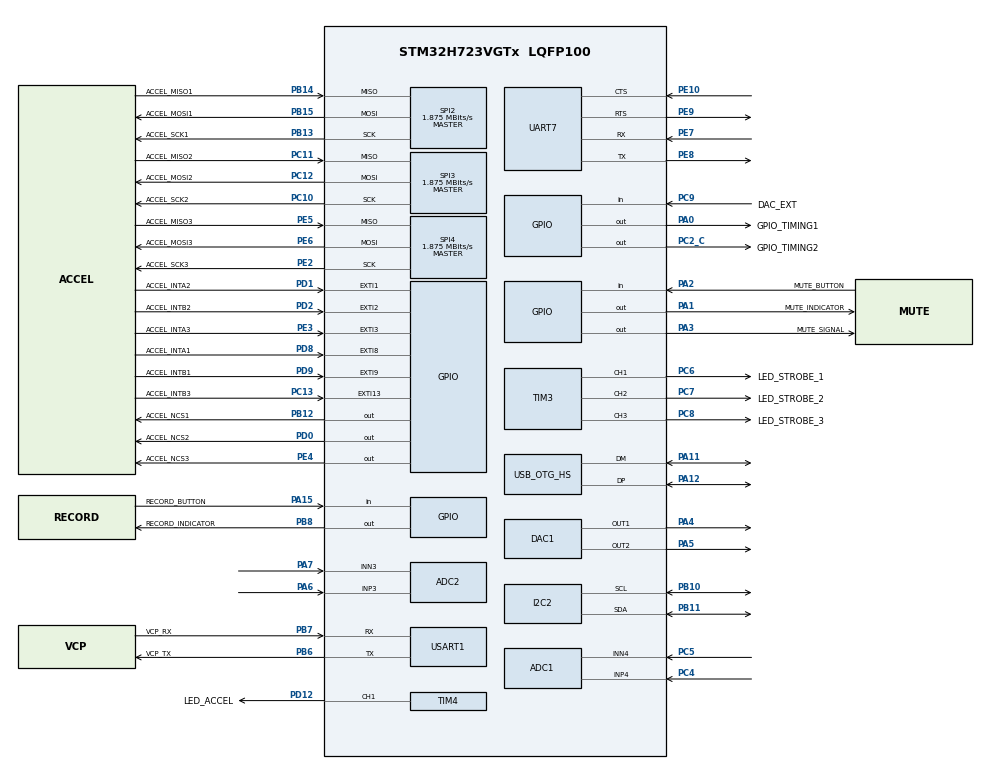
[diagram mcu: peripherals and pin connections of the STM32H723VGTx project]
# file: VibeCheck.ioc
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ADC1.Channel-0\#ChannelRegularConversion=ADC_CHANNEL_4
ADC1.ClockPrescaler=ADC_CLOCK_ASYNC_DIV2
ADC1.NbrOfConversionFlag=1
ADC1.OffsetNumber-0\#ChannelRegularConversion=ADC_OFFSET_NONE
ADC1.OffsetSignedSaturation-0\#ChannelRegularConversion=DISABLE
ADC1.Rank-0\#ChannelRegularConversion=1
ADC1.SamplingTime-0\#ChannelRegularConversion=ADC_SAMPLETIME_1CYCLE_5
ADC1.SingleDiff-0\#ChannelRegularConversion=ADC_DIFFERENTIAL_ENDED
ADC1.master=1
ADC2.Channel-1\#ChannelRegularConversion=ADC_CHANNEL_3
ADC2.ClockPrescaler=ADC_CLOCK_ASYNC_DIV2
ADC2.NbrOfConversionFlag=1
ADC2.OffsetNumber-1\#ChannelRegularConversion=ADC_OFFSET_NONE
ADC2.OffsetSignedSaturation-1\#ChannelRegularConversion=DISABLE
ADC2.Rank-1\#ChannelRegularConversion=1
ADC2.SamplingTime-1\#ChannelRegularConversion=ADC_SAMPLETIME_1CYCLE_5
ADC2.SingleDiff-1\#ChannelRegularConversion=ADC_DIFFERENTIAL_ENDED
CORTEX_M7.default_mode_Activation=1
DAC1.DAC1_OutputBuffer-DAC_OUT1=DAC_OUTPUTBUFFER_DISABLE
DAC1.DAC2_OutputBuffer-DAC_OUT2=DAC_OUTPUTBUFFER_DISABLE
DAC1.DAC_Channel-DAC_OUT1=DAC_CHANNEL_1
DAC1.DAC_Channel-DAC_OUT2=DAC_CHANNEL_2
DAC1.DAC_Trigger-DAC_OUT1=DAC_TRIGGER_T1_TRGO
DAC1.DAC_Trigger-DAC_OUT2=DAC_TRIGGER_T1_TRGO
Dma.DAC1_CH1.0.Direction=DMA_MEMORY_TO_PERIPH
Dma.DAC1_CH1.0.EventEnable=DISABLE
Dma.DAC1_CH1.0.FIFOMode=DMA_FIFOMODE_DISABLE
Dma.DAC1_CH1.0.Instance=DMA1_Stream0
Dma.DAC1_CH1.0.MemDataAlignment=DMA_MDATAALIGN_WORD
Dma.DAC1_CH1.0.MemInc=DMA_MINC_ENABLE
Dma.DAC1_CH1.0.Mode=DMA_CIRCULAR
Dma.DAC1_CH1.0.PeriphDataAlignment=DMA_PDATAALIGN_WORD
Dma.DAC1_CH1.0.PeriphInc=DMA_PINC_DISABLE
Dma.DAC1_CH1.0.Polarity=HAL_DMAMUX_REQ_GEN_RISING
Dma.DAC1_CH1.0.Priority=DMA_PRIORITY_LOW
Dma.DAC1_CH1.0.RequestNumber=1
Dma.DAC1_CH1.0.SignalID=NONE
Dma.DAC1_CH1.0.SyncEnable=DISABLE
Dma.DAC1_CH1.0.SyncPolarity=HAL_DMAMUX_SYNC_NO_EVENT
Dma.DAC1_CH1.0.SyncRequestNumber=1
Dma.DAC1_CH1.0.SyncSignalID=NONE
Dma.DAC1_CH2.1.Direction=DMA_MEMORY_TO_PERIPH
Dma.DAC1_CH2.1.EventEnable=DISABLE
Dma.DAC1_CH2.1.FIFOMode=DMA_FIFOMODE_DISABLE
Dma.DAC1_CH2.1.Instance=DMA1_Stream1
Dma.DAC1_CH2.1.MemDataAlignment=DMA_MDATAALIGN_WORD
Dma.DAC1_CH2.1.MemInc=DMA_MINC_ENABLE
Dma.DAC1_CH2.1.Mode=DMA_CIRCULAR
Dma.DAC1_CH2.1.PeriphDataAlignment=DMA_PDATAALIGN_WORD
Dma.DAC1_CH2.1.PeriphInc=DMA_PINC_DISABLE
Dma.DAC1_CH2.1.Polarity=HAL_DMAMUX_REQ_GEN_RISING
Dma.DAC1_CH2.1.Priority=DMA_PRIORITY_LOW
Dma.DAC1_CH2.1.RequestNumber=1
Dma.DAC1_CH2.1.SignalID=NONE
Dma.DAC1_CH2.1.SyncEnable=DISABLE
Dma.DAC1_CH2.1.SyncPolarity=HAL_DMAMUX_SYNC_NO_EVENT
Dma.DAC1_CH2.1.SyncRequestNumber=1
Dma.DAC1_CH2.1.SyncSignalID=NONE
Dma.Request0=DAC1_CH1
Dma.Request1=DAC1_CH2
Dma.Request2=TIM4_CH1
Dma.TIM4_CH1.2.Direction=DMA_MEMORY_TO_PERIPH
Dma.TIM4_CH1.2.EventEnable=DISABLE
Dma.TIM4_CH1.2.FIFOMode=DMA_FIFOMODE_DISABLE
Dma.TIM4_CH1.2.Instance=DMA1_Stream2
Dma.TIM4_CH1.2.MemDataAlignment=DMA_MDATAALIGN_HALFWORD
Dma.TIM4_CH1.2.MemInc=DMA_MINC_ENABLE
Dma.TIM4_CH1.2.Mode=DMA_NORMAL
Dma.TIM4_CH1.2.PeriphDataAlignment=DMA_PDATAALIGN_HALFWORD
Dma.TIM4_CH1.2.PeriphInc=DMA_PINC_DISABLE
Dma.TIM4_CH1.2.Polarity=HAL_DMAMUX_REQ_GEN_RISING
Dma.TIM4_CH1.2.Priority=DMA_PRIORITY_LOW
Dma.TIM4_CH1.2.RequestNumber=1
Dma.TIM4_CH1.2.SignalID=NONE
Dma.TIM4_CH1.2.SyncEnable=DISABLE
Dma.TIM4_CH1.2.SyncPolarity=HAL_DMAMUX_SYNC_NO_EVENT
Dma.TIM4_CH1.2.SyncRequestNumber=1
Dma.TIM4_CH1.2.SyncSignalID=NONE
I2C2.Timing=0x307075B1
Mcu.Family=STM32H7
Mcu.Name=STM32H723VGTx
Mcu.Package=LQFP100
NVIC.DMA1_Stream0_IRQn=true\:1\:1\:true\:false\:true\:false\:true\:true
NVIC.DMA1_Stream1_IRQn=true\:1\:1\:true\:false\:true\:false\:true\:true
NVIC.DMA1_Stream2_IRQn=true\:1\:1\:true\:false\:true\:false\:true\:true
NVIC.EXTI15_10_IRQn=true\:0\:0\:true\:false\:true\:true\:true\:true
NVIC.EXTI1_IRQn=true\:0\:0\:true\:false\:true\:true\:true\:true
NVIC.EXTI2_IRQn=true\:0\:0\:true\:false\:true\:true\:true\:true
NVIC.EXTI3_IRQn=true\:0\:0\:true\:false\:true\:true\:true\:true
NVIC.EXTI9_5_IRQn=true\:0\:0\:true\:false\:true\:true\:true\:true
NVIC.OTG_HS_IRQn=true\:1\:1\:true\:false\:true\:false\:true\:true
NVIC.PriorityGroup=NVIC_PRIORITYGROUP_2
NVIC.TIM3_IRQn=true\:1\:1\:true\:false\:true\:true\:true\:true
PA0.GPIO_Label=GPIO_TIMING1
PA0.Signal=GPIO_Output
PA1.GPIO_Label=MUTE_INDICATOR
PA1.PinState=GPIO_PIN_SET
PA1.Signal=GPIO_Output
PA11.Mode=Device_Only_FS
PA11.Signal=USB_OTG_HS_DM
PA12.Mode=Device_Only_FS
PA12.Signal=USB_OTG_HS_DP
PA13(JTMS/SWDIO).Mode=Trace_Asynchronous_SW
PA13(JTMS/SWDIO).Signal=DEBUG_JTMS-SWDIO
PA14(JTCK/SWCLK).Mode=Trace_Asynchronous_SW
PA14(JTCK/SWCLK).Signal=DEBUG_JTCK-SWCLK
PA15(JTDI).GPIO_Label=RECORD_BUTTON
PA15(JTDI).Signal=GPIO_Input
PA2.GPIO_Label=MUTE_BUTTON
PA2.Signal=GPIO_Input
PA3.GPIO_Label=MUTE_SIGNAL
PA3.PinState=GPIO_PIN_SET
PA3.Signal=GPIO_Output
PA4.Signal=COMP_DAC11_group
PA5.Signal=COMP_DAC12_group
PA6.Signal=ADCx_INP3
PA7.Signal=ADCx_INN3
PB10.Mode=I2C
PB10.Signal=I2C2_SCL
PB11.Mode=I2C
PB11.Signal=I2C2_SDA
PB12.GPIO_Label=ACCEL_NCS1
PB12.GPIO_Speed=GPIO_SPEED_FREQ_VERY_HIGH
PB12.PinState=GPIO_PIN_SET
PB12.Signal=GPIO_Output
PB13.GPIO_Label=ACCEL_SCK1
PB13.Mode=Full_Duplex_Master
PB13.Signal=SPI2_SCK
PB14.GPIO_Label=ACCEL_MISO1
PB14.Mode=Full_Duplex_Master
PB14.Signal=SPI2_MISO
PB15.GPIO_Label=ACCEL_MOSI1
PB15.Mode=Full_Duplex_Master
PB15.Signal=SPI2_MOSI
PB3(JTDO/TRACESWO).Mode=Trace_Asynchronous_SW
PB3(JTDO/TRACESWO).Signal=DEBUG_JTDO-SWO
PB6.GPIO_Label=VCP_TX
PB6.Mode=Asynchronous
PB6.Signal=USART1_TX
PB7.GPIO_Label=VCP_RX
PB7.Mode=Asynchronous
PB7.Signal=USART1_RX
PB8.GPIO_Label=RECORD_INDICATOR
PB8.Signal=GPIO_Output
PC10.GPIO_Label=ACCEL_SCK2
PC10.Mode=Full_Duplex_Master
PC10.Signal=SPI3_SCK
PC11.GPIO_Label=ACCEL_MISO2
PC11.Mode=Full_Duplex_Master
PC11.Signal=SPI3_MISO
PC12.GPIO_Label=ACCEL_MOSI2
PC12.Mode=Full_Duplex_Master
PC12.Signal=SPI3_MOSI
PC13.GPIO_Label=ACCEL_INTB3
PC13.Signal=GPXTI13
PC2_C.GPIO_Label=GPIO_TIMING2
PC2_C.Signal=GPIO_Output
PC4.Signal=ADCx_INP4
PC5.Signal=ADCx_INN4
PC6.GPIO_Label=LED_STROBE_1
PC6.Signal=S_TIM3_CH1
PC7.GPIO_Label=LED_STROBE_2
PC7.Signal=S_TIM3_CH2
PC8.GPIO_Label=LED_STROBE_3
PC8.Signal=S_TIM3_CH3
PC9.GPIO_Label=DAC_EXT
PC9.Signal=GPIO_Input
PD0.GPIO_Label=ACCEL_NCS2
PD0.GPIO_Speed=GPIO_SPEED_FREQ_VERY_HIGH
PD0.PinState=GPIO_PIN_SET
PD0.Signal=GPIO_Output
PD1.GPIO_Label=ACCEL_INTA2
PD1.Signal=GPXTI1
PD12.GPIO_Label=LED_ACCEL
PD12.Signal=S_TIM4_CH1
PD2.GPIO_Label=ACCEL_INTB2
PD2.Signal=GPXTI2
PD8.GPIO_Label=ACCEL_INTA1
PD8.Signal=GPXTI8
PD9.GPIO_Label=ACCEL_INTB1
PD9.Signal=GPXTI9
PE10.Mode=CTS_RTS
PE10.Signal=UART7_CTS
PE2.GPIO_Label=ACCEL_SCK3
PE2.Mode=Full_Duplex_Master
PE2.Signal=SPI4_SCK
PE3.GPIO_Label=ACCEL_INTA3
PE3.Signal=GPXTI3
PE4.GPIO_Label=ACCEL_NCS3
PE4.GPIO_Speed=GPIO_SPEED_FREQ_VERY_HIGH
PE4.PinState=GPIO_PIN_SET
PE4.Signal=GPIO_Output
PE5.GPIO_Label=ACCEL_MISO3
PE5.Mode=Full_Duplex_Master
PE5.Signal=SPI4_MISO
PE6.GPIO_Label=ACCEL_MOSI3
PE6.Mode=Full_Duplex_Master
PE6.Signal=SPI4_MOSI
PE7.Mode=Asynchronous
PE7.Signal=UART7_RX
PE8.Mode=Asynchronous
PE8.Signal=UART7_TX
PE9.Mode=CTS_RTS
PE9.Signal=UART7_RTS
PH0-OSC_IN.Mode=HSE-External-Oscillator
PH0-OSC_IN.Signal=RCC_OSC_IN
PH1-OSC_OUT.Mode=HSE-External-Oscillator
PH1-OSC_OUT.Signal=RCC_OSC_OUT
ProjectManager.HeapSize=0x3200
ProjectManager.StackSize=0x3200
ProjectManager.TargetToolchain=STM32CubeIDE
RCC.ADCFreq_Value=96000000
RCC.APB1Freq_Value=120000000
RCC.APB2Freq_Value=120000000
RCC.APB3Freq_Value=120000000
RCC.APB4Freq_Value=120000000
RCC.CortexFreq_Value=480000000
RCC.D1PPRE=RCC_APB3_DIV2
RCC.D2PPRE1=RCC_APB1_DIV2
RCC.D2PPRE2=RCC_APB2_DIV2
RCC.D3PPRE=RCC_APB4_DIV2
RCC.DIVM1=2
RCC.DIVM2=2
RCC.DIVN1=40
RCC.DIVN2=16
RCC.DIVP1=1
RCC.HCLKFreq_Value=240000000
RCC.HPRE=RCC_HCLK_DIV2
RCC.HSE_VALUE=24000000
RCC.PLL2FRACN=0
RCC.PLL3FRACN=0
RCC.PLLFRACN=0
RCC.PLLSourceVirtual=RCC_PLLSOURCE_HSE
RCC.SYSCLKFreq_VALUE=480000000
RCC.SYSCLKSource=RCC_SYSCLKSOURCE_PLLCLK
RCC.USBCLockSelection=RCC_USBCLKSOURCE_HSI48
RCC.USBFreq_Value=48000000
SH.ADCx_INN3.0=ADC2_INN3,IN3-Differential
SH.ADCx_INN4.0=ADC1_INN4,IN4-Differential
SH.ADCx_INP3.0=ADC2_INP3,IN3-Differential
SH.ADCx_INP4.0=ADC1_INP4,IN4-Differential
SH.COMP_DAC11_group.0=DAC1_OUT1,DAC_OUT1
SH.COMP_DAC12_group.0=DAC1_OUT2,DAC_OUT2
SH.S_TIM3_CH1.0=TIM3_CH1,PWM Generation1 CH1
SH.S_TIM3_CH2.0=TIM3_CH2,PWM Generation2 CH2
SH.S_TIM3_CH3.0=TIM3_CH3,PWM Generation3 CH3
SH.S_TIM4_CH1.0=TIM4_CH1,PWM Generation1 CH1
SPI2.BaudRatePrescaler=SPI_BAUDRATEPRESCALER_128
SPI2.CalculateBaudRate=1.875 MBits/s
SPI2.DataSize=SPI_DATASIZE_8BIT
SPI2.Direction=SPI_DIRECTION_2LINES
SPI2.IOSwap=SPI_IO_SWAP_DISABLE
SPI2.Mode=SPI_MODE_MASTER
SPI2.VirtualType=VM_MASTER
SPI3.BaudRatePrescaler=SPI_BAUDRATEPRESCALER_128
SPI3.CalculateBaudRate=1.875 MBits/s
SPI3.DataSize=SPI_DATASIZE_8BIT
SPI3.Direction=SPI_DIRECTION_2LINES
SPI3.Mode=SPI_MODE_MASTER
SPI3.VirtualType=VM_MASTER
SPI4.BaudRatePrescaler=SPI_BAUDRATEPRESCALER_64
SPI4.CalculateBaudRate=1.875 MBits/s
SPI4.DataSize=SPI_DATASIZE_8BIT
SPI4.Direction=SPI_DIRECTION_2LINES
SPI4.Mode=SPI_MODE_MASTER
SPI4.VirtualType=VM_MASTER
TIM1.TIM_MasterOutputTrigger=TIM_TRGO_UPDATE
TIM2.Prescaler=239
TIM2.TIM_MasterOutputTrigger=TIM_TRGO_UPDATE
TIM3.Channel-PWM\ Generation1\ CH1=TIM_CHANNEL_1
TIM3.Channel-PWM\ Generation2\ CH2=TIM_CHANNEL_2
TIM3.Channel-PWM\ Generation3\ CH3=TIM_CHANNEL_3
TIM4.Channel-PWM\ Generation1\ CH1=TIM_CHANNEL_1
USART1.VirtualMode-Asynchronous=VM_ASYNC
USB_DEVICE.APP_RX_DATA_SIZE=32768
USB_DEVICE.APP_TX_DATA_SIZE=2048
USB_DEVICE.CLASS_NAME_HS=CDC
USB_DEVICE.MANUFACTURER_STRING=Harris Lab
USB_DEVICE.PRODUCT_STRING_CDC_HS=VibeCheck
USB_DEVICE.VirtualMode=Cdc
USB_DEVICE.VirtualModeHS=Cdc_HS
USB_OTG_HS.VirtualMode-Device_Only_FS=Device_Only_FS
USB_OTG_HS.dma_enable-Device_Only_FS=DISABLE
VP_MEMORYMAP_VS_MEMORYMAP.Mode=CurAppReg
VP_TIM1_VS_ClockSourceINT.Mode=Internal
VP_TIM2_VS_ClockSourceINT.Mode=Internal
VP_TIM3_VS_ClockSourceINT.Mode=Internal
VP_TIM4_VS_ClockSourceINT.Mode=Internal
VP_USB_DEVICE_VS_USB_DEVICE_CDC_HS.Mode=CDC_HS
board=custom

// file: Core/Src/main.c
/* USER CODE BEGIN Header */
/**
  ******************************************************************************
  * @file           : main.c
  * @brief          : Main program body
  ******************************************************************************
  * @attention
  *
  * Copyright (c) 2024 STMicroelectronics.
  * All rights reserved.
  *
  * This software is licensed under terms that can be found in the LICENSE file
  * in the root directory of this software component.
  * If no LICENSE file comes with this software, it is provided AS-IS.
  *
  ******************************************************************************
  */
/* USER CODE END Header */
#include "main.h"
#include "usb_device.h"

/* USER CODE BEGIN Includes */

#include "vibecheck.h"

/* USER CODE END Includes */

ADC_HandleTypeDef hadc1;
ADC_HandleTypeDef hadc2;

DAC_HandleTypeDef hdac1;
DMA_HandleTypeDef hdma_dac1_ch1;
DMA_HandleTypeDef hdma_dac1_ch2;

I2C_HandleTypeDef hi2c2;

SPI_HandleTypeDef hspi2;
SPI_HandleTypeDef hspi3;
SPI_HandleTypeDef hspi4;

TIM_HandleTypeDef htim1;
TIM_HandleTypeDef htim2;
TIM_HandleTypeDef htim3;
TIM_HandleTypeDef htim4;
DMA_HandleTypeDef hdma_tim4_ch1;

UART_HandleTypeDef huart7;
UART_HandleTypeDef huart1;

/* USER CODE BEGIN PV */
VibeCheck vc;
/* USER CODE END PV */

void SystemClock_Config(void);
void PeriphCommonClock_Config(void);
static void MPU_Config(void);
static void MX_GPIO_Init(void);
static void MX_DMA_Init(void);
static void MX_DAC1_Init(void);
static void MX_I2C2_Init(void);
static void MX_SPI2_Init(void);
static void MX_SPI3_Init(void);
static void MX_SPI4_Init(void);
static void MX_TIM4_Init(void);
static void MX_TIM3_Init(void);
static void MX_USART1_UART_Init(void);
static void MX_TIM1_Init(void);
static void MX_TIM2_Init(void);
static void MX_ADC1_Init(void);
static void MX_ADC2_Init(void);
static void MX_UART7_Init(void);

/* USER CODE BEGIN 0 */

void HAL_TIM_PeriodElapsedCallback(TIM_HandleTypeDef *htim)
{
	VibeCheckStrobe_PeriodElapsedUpdate(&vc.strobe);
}

void HAL_DAC_ConvHalfCpltCallbackCh1(DAC_HandleTypeDef* hdac)
{
	VibeCheckWaveGen_DMAHalfCpltCallback(&vc.wavegen);
}

void HAL_DAC_ConvCpltCallbackCh1(DAC_HandleTypeDef* hdac)
{
	VibeCheckWaveGen_DMACpltCallback(&vc.wavegen);
}

void HAL_GPIO_EXTI_Callback(uint16_t GPIO_Pin)
{
	VibeCheckSensor_EXTICallback(&vc.sensor, GPIO_Pin);
}

/* USER CODE END 0 */

int main(void)
{

  /* MPU Configuration--------------------------------------------------------*/
  MPU_Config();

  /* MCU Configuration--------------------------------------------------------*/

  /* Reset of all peripherals, Initializes the Flash interface and the Systick. */
  HAL_Init();

  /* Configure the system clock */
  SystemClock_Config();

  /* Configure the peripherals common clocks */
  PeriphCommonClock_Config();

  /* Initialize all configured peripherals */
  MX_GPIO_Init();
  MX_DMA_Init();
  MX_DAC1_Init();
  MX_I2C2_Init();
  MX_SPI2_Init();
  MX_SPI3_Init();
  MX_SPI4_Init();
  MX_TIM4_Init();
  MX_TIM3_Init();
  MX_USART1_UART_Init();
  MX_TIM1_Init();
  MX_TIM2_Init();
  MX_ADC1_Init();
  MX_ADC2_Init();
  MX_UART7_Init();
  MX_USB_DEVICE_Init();

  /* Infinite loop */
  /* USER CODE BEGIN WHILE */

  HAL_TIM_Base_Start(&htim2);  /* start the timer for sensor data time stamps */
  VibeCheck_Init(&vc, &htim3, &htim1, &hdac1, &htim4, &(TIM2->CNT), &hspi2, &hspi3, &hspi4);

  while (1)
  {

	  VibeCheck_Loop(&vc);

    /* USER CODE END WHILE */

  }
}

void SystemClock_Config(void)
{
  RCC_OscInitTypeDef RCC_OscInitStruct = {0};
  RCC_ClkInitTypeDef RCC_ClkInitStruct = {0};

  /** Supply configuration update enable
  */
  HAL_PWREx_ConfigSupply(PWR_LDO_SUPPLY);

  /** Configure the main internal regulator output voltage
  */
  __HAL_PWR_VOLTAGESCALING_CONFIG(PWR_REGULATOR_VOLTAGE_SCALE0);

  while(!__HAL_PWR_GET_FLAG(PWR_FLAG_VOSRDY)) {}

  /** Initializes the RCC Oscillators according to the specified parameters
  * in the RCC_OscInitTypeDef structure.
  */
  RCC_OscInitStruct.OscillatorType = RCC_OSCILLATORTYPE_HSI48|RCC_OSCILLATORTYPE_HSE;
  RCC_OscInitStruct.HSEState = RCC_HSE_ON;
  RCC_OscInitStruct.HSI48State = RCC_HSI48_ON;
  RCC_OscInitStruct.PLL.PLLState = RCC_PLL_ON;
  RCC_OscInitStruct.PLL.PLLSource = RCC_PLLSOURCE_HSE;
  RCC_OscInitStruct.PLL.PLLM = 2;
  RCC_OscInitStruct.PLL.PLLN = 40;
  RCC_OscInitStruct.PLL.PLLP = 1;
  RCC_OscInitStruct.PLL.PLLQ = 2;
  RCC_OscInitStruct.PLL.PLLR = 2;
  RCC_OscInitStruct.PLL.PLLRGE = RCC_PLL1VCIRANGE_3;
  RCC_OscInitStruct.PLL.PLLVCOSEL = RCC_PLL1VCOWIDE;
  RCC_OscInitStruct.PLL.PLLFRACN = 0;
  if (HAL_RCC_OscConfig(&RCC_OscInitStruct) != HAL_OK)
  {
    Error_Handler();
  }

  /** Initializes the CPU, AHB and APB buses clocks
  */
  RCC_ClkInitStruct.ClockType = RCC_CLOCKTYPE_HCLK|RCC_CLOCKTYPE_SYSCLK
                              |RCC_CLOCKTYPE_PCLK1|RCC_CLOCKTYPE_PCLK2
                              |RCC_CLOCKTYPE_D3PCLK1|RCC_CLOCKTYPE_D1PCLK1;
  RCC_ClkInitStruct.SYSCLKSource = RCC_SYSCLKSOURCE_PLLCLK;
  RCC_ClkInitStruct.SYSCLKDivider = RCC_SYSCLK_DIV1;
  RCC_ClkInitStruct.AHBCLKDivider = RCC_HCLK_DIV2;
  RCC_ClkInitStruct.APB3CLKDivider = RCC_APB3_DIV2;
  RCC_ClkInitStruct.APB1CLKDivider = RCC_APB1_DIV2;
  RCC_ClkInitStruct.APB2CLKDivider = RCC_APB2_DIV2;
  RCC_ClkInitStruct.APB4CLKDivider = RCC_APB4_DIV2;

  if (HAL_RCC_ClockConfig(&RCC_ClkInitStruct, FLASH_LATENCY_3) != HAL_OK)
  {
    Error_Handler();
  }
}

void PeriphCommonClock_Config(void)
{
  RCC_PeriphCLKInitTypeDef PeriphClkInitStruct = {0};

  /** Initializes the peripherals clock
  */
  PeriphClkInitStruct.PeriphClockSelection = RCC_PERIPHCLK_ADC;
  PeriphClkInitStruct.PLL2.PLL2M = 2;
  PeriphClkInitStruct.PLL2.PLL2N = 16;
  PeriphClkInitStruct.PLL2.PLL2P = 2;
  PeriphClkInitStruct.PLL2.PLL2Q = 2;
  PeriphClkInitStruct.PLL2.PLL2R = 2;
  PeriphClkInitStruct.PLL2.PLL2RGE = RCC_PLL2VCIRANGE_3;
  PeriphClkInitStruct.PLL2.PLL2VCOSEL = RCC_PLL2VCOWIDE;
  PeriphClkInitStruct.PLL2.PLL2FRACN = 0;
  PeriphClkInitStruct.AdcClockSelection = RCC_ADCCLKSOURCE_PLL2;
  if (HAL_RCCEx_PeriphCLKConfig(&PeriphClkInitStruct) != HAL_OK)
  {
    Error_Handler();
  }
}

static void MX_ADC1_Init(void)
{

  ADC_MultiModeTypeDef multimode = {0};
  ADC_ChannelConfTypeDef sConfig = {0};

  /** Common config
  */
  hadc1.Instance = ADC1;
  hadc1.Init.ClockPrescaler = ADC_CLOCK_ASYNC_DIV2;
  hadc1.Init.Resolution = ADC_RESOLUTION_16B;
  hadc1.Init.ScanConvMode = ADC_SCAN_DISABLE;
  hadc1.Init.EOCSelection = ADC_EOC_SINGLE_CONV;
  hadc1.Init.LowPowerAutoWait = DISABLE;
  hadc1.Init.ContinuousConvMode = DISABLE;
  hadc1.Init.NbrOfConversion = 1;
  hadc1.Init.DiscontinuousConvMode = DISABLE;
  hadc1.Init.ExternalTrigConv = ADC_SOFTWARE_START;
  hadc1.Init.ExternalTrigConvEdge = ADC_EXTERNALTRIGCONVEDGE_NONE;
  hadc1.Init.ConversionDataManagement = ADC_CONVERSIONDATA_DR;
  hadc1.Init.Overrun = ADC_OVR_DATA_PRESERVED;
  hadc1.Init.LeftBitShift = ADC_LEFTBITSHIFT_NONE;
  hadc1.Init.OversamplingMode = DISABLE;
  hadc1.Init.Oversampling.Ratio = 1;
  if (HAL_ADC_Init(&hadc1) != HAL_OK)
  {
    Error_Handler();
  }

  /** Configure the ADC multi-mode
  */
  multimode.Mode = ADC_MODE_INDEPENDENT;
  if (HAL_ADCEx_MultiModeConfigChannel(&hadc1, &multimode) != HAL_OK)
  {
    Error_Handler();
  }

  /** Configure Regular Channel
  */
  sConfig.Channel = ADC_CHANNEL_4;
  sConfig.Rank = ADC_REGULAR_RANK_1;
  sConfig.SamplingTime = ADC_SAMPLETIME_1CYCLE_5;
  sConfig.SingleDiff = ADC_DIFFERENTIAL_ENDED;
  sConfig.OffsetNumber = ADC_OFFSET_NONE;
  sConfig.Offset = 0;
  sConfig.OffsetSignedSaturation = DISABLE;
  if (HAL_ADC_ConfigChannel(&hadc1, &sConfig) != HAL_OK)
  {
    Error_Handler();
  }

}

static void MX_ADC2_Init(void)
{

  ADC_ChannelConfTypeDef sConfig = {0};

  /** Common config
  */
  hadc2.Instance = ADC2;
  hadc2.Init.ClockPrescaler = ADC_CLOCK_ASYNC_DIV2;
  hadc2.Init.Resolution = ADC_RESOLUTION_16B;
  hadc2.Init.ScanConvMode = ADC_SCAN_DISABLE;
  hadc2.Init.EOCSelection = ADC_EOC_SINGLE_CONV;
  hadc2.Init.LowPowerAutoWait = DISABLE;
  hadc2.Init.ContinuousConvMode = DISABLE;
  hadc2.Init.NbrOfConversion = 1;
  hadc2.Init.DiscontinuousConvMode = DISABLE;
  hadc2.Init.ExternalTrigConv = ADC_SOFTWARE_START;
  hadc2.Init.ExternalTrigConvEdge = ADC_EXTERNALTRIGCONVEDGE_NONE;
  hadc2.Init.ConversionDataManagement = ADC_CONVERSIONDATA_DR;
  hadc2.Init.Overrun = ADC_OVR_DATA_PRESERVED;
  hadc2.Init.LeftBitShift = ADC_LEFTBITSHIFT_NONE;
  hadc2.Init.OversamplingMode = DISABLE;
  hadc2.Init.Oversampling.Ratio = 1;
  if (HAL_ADC_Init(&hadc2) != HAL_OK)
  {
    Error_Handler();
  }

  /** Configure Regular Channel
  */
  sConfig.Channel = ADC_CHANNEL_3;
  sConfig.Rank = ADC_REGULAR_RANK_1;
  sConfig.SamplingTime = ADC_SAMPLETIME_1CYCLE_5;
  sConfig.SingleDiff = ADC_DIFFERENTIAL_ENDED;
  sConfig.OffsetNumber = ADC_OFFSET_NONE;
  sConfig.Offset = 0;
  sConfig.OffsetSignedSaturation = DISABLE;
  if (HAL_ADC_ConfigChannel(&hadc2, &sConfig) != HAL_OK)
  {
    Error_Handler();
  }

}

static void MX_DAC1_Init(void)
{

  DAC_ChannelConfTypeDef sConfig = {0};

  /** DAC Initialization
  */
  hdac1.Instance = DAC1;
  if (HAL_DAC_Init(&hdac1) != HAL_OK)
  {
    Error_Handler();
  }

  /** DAC channel OUT1 config
  */
  sConfig.DAC_SampleAndHold = DAC_SAMPLEANDHOLD_DISABLE;
  sConfig.DAC_Trigger = DAC_TRIGGER_T1_TRGO;
  sConfig.DAC_OutputBuffer = DAC_OUTPUTBUFFER_DISABLE;
  sConfig.DAC_ConnectOnChipPeripheral = DAC_CHIPCONNECT_DISABLE;
  sConfig.DAC_UserTrimming = DAC_TRIMMING_FACTORY;
  if (HAL_DAC_ConfigChannel(&hdac1, &sConfig, DAC_CHANNEL_1) != HAL_OK)
  {
    Error_Handler();
  }

  /** DAC channel OUT2 config
  */
  if (HAL_DAC_ConfigChannel(&hdac1, &sConfig, DAC_CHANNEL_2) != HAL_OK)
  {
    Error_Handler();
  }

}

static void MX_I2C2_Init(void)
{

  hi2c2.Instance = I2C2;
  hi2c2.Init.Timing = 0x307075B1;
  hi2c2.Init.OwnAddress1 = 0;
  hi2c2.Init.AddressingMode = I2C_ADDRESSINGMODE_7BIT;
  hi2c2.Init.DualAddressMode = I2C_DUALADDRESS_DISABLE;
  hi2c2.Init.OwnAddress2 = 0;
  hi2c2.Init.OwnAddress2Masks = I2C_OA2_NOMASK;
  hi2c2.Init.GeneralCallMode = I2C_GENERALCALL_DISABLE;
  hi2c2.Init.NoStretchMode = I2C_NOSTRETCH_DISABLE;
  if (HAL_I2C_Init(&hi2c2) != HAL_OK)
  {
    Error_Handler();
  }

  /** Configure Analogue filter
  */
  if (HAL_I2CEx_ConfigAnalogFilter(&hi2c2, I2C_ANALOGFILTER_ENABLE) != HAL_OK)
  {
    Error_Handler();
  }

  /** Configure Digital filter
  */
  if (HAL_I2CEx_ConfigDigitalFilter(&hi2c2, 0) != HAL_OK)
  {
    Error_Handler();
  }

}

static void MX_SPI2_Init(void)
{

  /* SPI2 parameter configuration*/
  hspi2.Instance = SPI2;
  hspi2.Init.Mode = SPI_MODE_MASTER;
  hspi2.Init.Direction = SPI_DIRECTION_2LINES;
  hspi2.Init.DataSize = SPI_DATASIZE_8BIT;
  hspi2.Init.CLKPolarity = SPI_POLARITY_LOW;
  hspi2.Init.CLKPhase = SPI_PHASE_1EDGE;
  hspi2.Init.NSS = SPI_NSS_SOFT;
  hspi2.Init.BaudRatePrescaler = SPI_BAUDRATEPRESCALER_128;
  hspi2.Init.FirstBit = SPI_FIRSTBIT_MSB;
  hspi2.Init.TIMode = SPI_TIMODE_DISABLE;
  hspi2.Init.CRCCalculation = SPI_CRCCALCULATION_DISABLE;
  hspi2.Init.CRCPolynomial = 0x0;
  hspi2.Init.NSSPMode = SPI_NSS_PULSE_ENABLE;
  hspi2.Init.NSSPolarity = SPI_NSS_POLARITY_LOW;
  hspi2.Init.FifoThreshold = SPI_FIFO_THRESHOLD_01DATA;
  hspi2.Init.TxCRCInitializationPattern = SPI_CRC_INITIALIZATION_ALL_ZERO_PATTERN;
  hspi2.Init.RxCRCInitializationPattern = SPI_CRC_INITIALIZATION_ALL_ZERO_PATTERN;
  hspi2.Init.MasterSSIdleness = SPI_MASTER_SS_IDLENESS_00CYCLE;
  hspi2.Init.MasterInterDataIdleness = SPI_MASTER_INTERDATA_IDLENESS_00CYCLE;
  hspi2.Init.MasterReceiverAutoSusp = SPI_MASTER_RX_AUTOSUSP_DISABLE;
  hspi2.Init.MasterKeepIOState = SPI_MASTER_KEEP_IO_STATE_DISABLE;
  hspi2.Init.IOSwap = SPI_IO_SWAP_DISABLE;
  if (HAL_SPI_Init(&hspi2) != HAL_OK)
  {
    Error_Handler();
  }

}

static void MX_SPI3_Init(void)
{

  /* SPI3 parameter configuration*/
  hspi3.Instance = SPI3;
  hspi3.Init.Mode = SPI_MODE_MASTER;
  hspi3.Init.Direction = SPI_DIRECTION_2LINES;
  hspi3.Init.DataSize = SPI_DATASIZE_8BIT;
  hspi3.Init.CLKPolarity = SPI_POLARITY_LOW;
  hspi3.Init.CLKPhase = SPI_PHASE_1EDGE;
  hspi3.Init.NSS = SPI_NSS_SOFT;
  hspi3.Init.BaudRatePrescaler = SPI_BAUDRATEPRESCALER_128;
  hspi3.Init.FirstBit = SPI_FIRSTBIT_MSB;
  hspi3.Init.TIMode = SPI_TIMODE_DISABLE;
  hspi3.Init.CRCCalculation = SPI_CRCCALCULATION_DISABLE;
  hspi3.Init.CRCPolynomial = 0x0;
  hspi3.Init.NSSPMode = SPI_NSS_PULSE_ENABLE;
  hspi3.Init.NSSPolarity = SPI_NSS_POLARITY_LOW;
  hspi3.Init.FifoThreshold = SPI_FIFO_THRESHOLD_01DATA;
  hspi3.Init.TxCRCInitializationPattern = SPI_CRC_INITIALIZATION_ALL_ZERO_PATTERN;
  hspi3.Init.RxCRCInitializationPattern = SPI_CRC_INITIALIZATION_ALL_ZERO_PATTERN;
  hspi3.Init.MasterSSIdleness = SPI_MASTER_SS_IDLENESS_00CYCLE;
  hspi3.Init.MasterInterDataIdleness = SPI_MASTER_INTERDATA_IDLENESS_00CYCLE;
  hspi3.Init.MasterReceiverAutoSusp = SPI_MASTER_RX_AUTOSUSP_DISABLE;
  hspi3.Init.MasterKeepIOState = SPI_MASTER_KEEP_IO_STATE_DISABLE;
  hspi3.Init.IOSwap = SPI_IO_SWAP_DISABLE;
  if (HAL_SPI_Init(&hspi3) != HAL_OK)
  {
    Error_Handler();
  }

}

static void MX_SPI4_Init(void)
{

  /* SPI4 parameter configuration*/
  hspi4.Instance = SPI4;
  hspi4.Init.Mode = SPI_MODE_MASTER;
  hspi4.Init.Direction = SPI_DIRECTION_2LINES;
  hspi4.Init.DataSize = SPI_DATASIZE_8BIT;
  hspi4.Init.CLKPolarity = SPI_POLARITY_LOW;
  hspi4.Init.CLKPhase = SPI_PHASE_1EDGE;
  hspi4.Init.NSS = SPI_NSS_SOFT;
  hspi4.Init.BaudRatePrescaler = SPI_BAUDRATEPRESCALER_64;
  hspi4.Init.FirstBit = SPI_FIRSTBIT_MSB;
  hspi4.Init.TIMode = SPI_TIMODE_DISABLE;
  hspi4.Init.CRCCalculation = SPI_CRCCALCULATION_DISABLE;
  hspi4.Init.CRCPolynomial = 0x0;
  hspi4.Init.NSSPMode = SPI_NSS_PULSE_ENABLE;
  hspi4.Init.NSSPolarity = SPI_NSS_POLARITY_LOW;
  hspi4.Init.FifoThreshold = SPI_FIFO_THRESHOLD_01DATA;
  hspi4.Init.TxCRCInitializationPattern = SPI_CRC_INITIALIZATION_ALL_ZERO_PATTERN;
  hspi4.Init.RxCRCInitializationPattern = SPI_CRC_INITIALIZATION_ALL_ZERO_PATTERN;
  hspi4.Init.MasterSSIdleness = SPI_MASTER_SS_IDLENESS_00CYCLE;
  hspi4.Init.MasterInterDataIdleness = SPI_MASTER_INTERDATA_IDLENESS_00CYCLE;
  hspi4.Init.MasterReceiverAutoSusp = SPI_MASTER_RX_AUTOSUSP_DISABLE;
  hspi4.Init.MasterKeepIOState = SPI_MASTER_KEEP_IO_STATE_DISABLE;
  hspi4.Init.IOSwap = SPI_IO_SWAP_DISABLE;
  if (HAL_SPI_Init(&hspi4) != HAL_OK)
  {
    Error_Handler();
  }

}

static void MX_TIM1_Init(void)
{

  TIM_ClockConfigTypeDef sClockSourceConfig = {0};
  TIM_MasterConfigTypeDef sMasterConfig = {0};

  htim1.Instance = TIM1;
  htim1.Init.Prescaler = 0;
  htim1.Init.CounterMode = TIM_COUNTERMODE_UP;
  htim1.Init.Period = 65535;
  htim1.Init.ClockDivision = TIM_CLOCKDIVISION_DIV1;
  htim1.Init.RepetitionCounter = 0;
  htim1.Init.AutoReloadPreload = TIM_AUTORELOAD_PRELOAD_DISABLE;
  if (HAL_TIM_Base_Init(&htim1) != HAL_OK)
  {
    Error_Handler();
  }
  sClockSourceConfig.ClockSource = TIM_CLOCKSOURCE_INTERNAL;
  if (HAL_TIM_ConfigClockSource(&htim1, &sClockSourceConfig) != HAL_OK)
  {
    Error_Handler();
  }
  sMasterConfig.MasterOutputTrigger = TIM_TRGO_UPDATE;
  sMasterConfig.MasterOutputTrigger2 = TIM_TRGO2_RESET;
  sMasterConfig.MasterSlaveMode = TIM_MASTERSLAVEMODE_DISABLE;
  if (HAL_TIMEx_MasterConfigSynchronization(&htim1, &sMasterConfig) != HAL_OK)
  {
    Error_Handler();
  }

}

static void MX_TIM2_Init(void)
{

  TIM_ClockConfigTypeDef sClockSourceConfig = {0};
  TIM_MasterConfigTypeDef sMasterConfig = {0};

  htim2.Instance = TIM2;
  htim2.Init.Prescaler = 239;
  htim2.Init.CounterMode = TIM_COUNTERMODE_UP;
  htim2.Init.Period = 4294967295;
  htim2.Init.ClockDivision = TIM_CLOCKDIVISION_DIV1;
  htim2.Init.AutoReloadPreload = TIM_AUTORELOAD_PRELOAD_DISABLE;
  if (HAL_TIM_Base_Init(&htim2) != HAL_OK)
  {
    Error_Handler();
  }
  sClockSourceConfig.ClockSource = TIM_CLOCKSOURCE_INTERNAL;
  if (HAL_TIM_ConfigClockSource(&htim2, &sClockSourceConfig) != HAL_OK)
  {
    Error_Handler();
  }
  sMasterConfig.MasterOutputTrigger = TIM_TRGO_UPDATE;
  sMasterConfig.MasterSlaveMode = TIM_MASTERSLAVEMODE_DISABLE;
  if (HAL_TIMEx_MasterConfigSynchronization(&htim2, &sMasterConfig) != HAL_OK)
  {
    Error_Handler();
  }

}

static void MX_TIM3_Init(void)
{

  TIM_ClockConfigTypeDef sClockSourceConfig = {0};
  TIM_MasterConfigTypeDef sMasterConfig = {0};
  TIM_OC_InitTypeDef sConfigOC = {0};

  htim3.Instance = TIM3;
  htim3.Init.Prescaler = 0;
  htim3.Init.CounterMode = TIM_COUNTERMODE_UP;
  htim3.Init.Period = 65535;
  htim3.Init.ClockDivision = TIM_CLOCKDIVISION_DIV1;
  htim3.Init.AutoReloadPreload = TIM_AUTORELOAD_PRELOAD_DISABLE;
  if (HAL_TIM_Base_Init(&htim3) != HAL_OK)
  {
    Error_Handler();
  }
  sClockSourceConfig.ClockSource = TIM_CLOCKSOURCE_INTERNAL;
  if (HAL_TIM_ConfigClockSource(&htim3, &sClockSourceConfig) != HAL_OK)
  {
    Error_Handler();
  }
  if (HAL_TIM_PWM_Init(&htim3) != HAL_OK)
  {
    Error_Handler();
  }
  sMasterConfig.MasterOutputTrigger = TIM_TRGO_RESET;
  sMasterConfig.MasterSlaveMode = TIM_MASTERSLAVEMODE_DISABLE;
  if (HAL_TIMEx_MasterConfigSynchronization(&htim3, &sMasterConfig) != HAL_OK)
  {
    Error_Handler();
  }
  sConfigOC.OCMode = TIM_OCMODE_PWM1;
  sConfigOC.Pulse = 0;
  sConfigOC.OCPolarity = TIM_OCPOLARITY_HIGH;
  sConfigOC.OCFastMode = TIM_OCFAST_DISABLE;
  if (HAL_TIM_PWM_ConfigChannel(&htim3, &sConfigOC, TIM_CHANNEL_1) != HAL_OK)
  {
    Error_Handler();
  }
  if (HAL_TIM_PWM_ConfigChannel(&htim3, &sConfigOC, TIM_CHANNEL_2) != HAL_OK)
  {
    Error_Handler();
  }
  if (HAL_TIM_PWM_ConfigChannel(&htim3, &sConfigOC, TIM_CHANNEL_3) != HAL_OK)
  {
    Error_Handler();
  }
  HAL_TIM_MspPostInit(&htim3);

}

static void MX_TIM4_Init(void)
{

  TIM_ClockConfigTypeDef sClockSourceConfig = {0};
  TIM_MasterConfigTypeDef sMasterConfig = {0};
  TIM_OC_InitTypeDef sConfigOC = {0};

  htim4.Instance = TIM4;
  htim4.Init.Prescaler = 0;
  htim4.Init.CounterMode = TIM_COUNTERMODE_UP;
  htim4.Init.Period = 65535;
  htim4.Init.ClockDivision = TIM_CLOCKDIVISION_DIV1;
  htim4.Init.AutoReloadPreload = TIM_AUTORELOAD_PRELOAD_DISABLE;
  if (HAL_TIM_Base_Init(&htim4) != HAL_OK)
  {
    Error_Handler();
  }
  sClockSourceConfig.ClockSource = TIM_CLOCKSOURCE_INTERNAL;
  if (HAL_TIM_ConfigClockSource(&htim4, &sClockSourceConfig) != HAL_OK)
  {
    Error_Handler();
  }
  if (HAL_TIM_PWM_Init(&htim4) != HAL_OK)
  {
    Error_Handler();
  }
  sMasterConfig.MasterOutputTrigger = TIM_TRGO_RESET;
  sMasterConfig.MasterSlaveMode = TIM_MASTERSLAVEMODE_DISABLE;
  if (HAL_TIMEx_MasterConfigSynchronization(&htim4, &sMasterConfig) != HAL_OK)
  {
    Error_Handler();
  }
  sConfigOC.OCMode = TIM_OCMODE_PWM1;
  sConfigOC.Pulse = 0;
  sConfigOC.OCPolarity = TIM_OCPOLARITY_HIGH;
  sConfigOC.OCFastMode = TIM_OCFAST_DISABLE;
  if (HAL_TIM_PWM_ConfigChannel(&htim4, &sConfigOC, TIM_CHANNEL_1) != HAL_OK)
  {
    Error_Handler();
  }
  HAL_TIM_MspPostInit(&htim4);

}

static void MX_UART7_Init(void)
{

  huart7.Instance = UART7;
  huart7.Init.BaudRate = 115200;
  huart7.Init.WordLength = UART_WORDLENGTH_8B;
  huart7.Init.StopBits = UART_STOPBITS_1;
  huart7.Init.Parity = UART_PARITY_NONE;
  huart7.Init.Mode = UART_MODE_TX_RX;
  huart7.Init.HwFlowCtl = UART_HWCONTROL_RTS_CTS;
  huart7.Init.OverSampling = UART_OVERSAMPLING_16;
  huart7.Init.OneBitSampling = UART_ONE_BIT_SAMPLE_DISABLE;
  huart7.Init.ClockPrescaler = UART_PRESCALER_DIV1;
  huart7.AdvancedInit.AdvFeatureInit = UART_ADVFEATURE_NO_INIT;
  if (HAL_UART_Init(&huart7) != HAL_OK)
  {
    Error_Handler();
  }
  if (HAL_UARTEx_SetTxFifoThreshold(&huart7, UART_TXFIFO_THRESHOLD_1_8) != HAL_OK)
  {
    Error_Handler();
  }
  if (HAL_UARTEx_SetRxFifoThreshold(&huart7, UART_RXFIFO_THRESHOLD_1_8) != HAL_OK)
  {
    Error_Handler();
  }
  if (HAL_UARTEx_DisableFifoMode(&huart7) != HAL_OK)
  {
    Error_Handler();
  }

}

static void MX_USART1_UART_Init(void)
{

  huart1.Instance = USART1;
  huart1.Init.BaudRate = 115200;
  huart1.Init.WordLength = UART_WORDLENGTH_8B;
  huart1.Init.StopBits = UART_STOPBITS_1;
  huart1.Init.Parity = UART_PARITY_NONE;
  huart1.Init.Mode = UART_MODE_TX_RX;
  huart1.Init.HwFlowCtl = UART_HWCONTROL_NONE;
  huart1.Init.OverSampling = UART_OVERSAMPLING_16;
  huart1.Init.OneBitSampling = UART_ONE_BIT_SAMPLE_DISABLE;
  huart1.Init.ClockPrescaler = UART_PRESCALER_DIV1;
  huart1.AdvancedInit.AdvFeatureInit = UART_ADVFEATURE_NO_INIT;
  if (HAL_UART_Init(&huart1) != HAL_OK)
  {
    Error_Handler();
  }
  if (HAL_UARTEx_SetTxFifoThreshold(&huart1, UART_TXFIFO_THRESHOLD_1_8) != HAL_OK)
  {
    Error_Handler();
  }
  if (HAL_UARTEx_SetRxFifoThreshold(&huart1, UART_RXFIFO_THRESHOLD_1_8) != HAL_OK)
  {
    Error_Handler();
  }
  if (HAL_UARTEx_DisableFifoMode(&huart1) != HAL_OK)
  {
    Error_Handler();
  }

}

static void MX_DMA_Init(void)
{

  /* DMA controller clock enable */
  __HAL_RCC_DMA1_CLK_ENABLE();

  /* DMA interrupt init */
  /* DMA1_Stream0_IRQn interrupt configuration */
  HAL_NVIC_SetPriority(DMA1_Stream0_IRQn, 1, 1);
  HAL_NVIC_EnableIRQ(DMA1_Stream0_IRQn);
  /* DMA1_Stream1_IRQn interrupt configuration */
  HAL_NVIC_SetPriority(DMA1_Stream1_IRQn, 1, 1);
  HAL_NVIC_EnableIRQ(DMA1_Stream1_IRQn);
  /* DMA1_Stream2_IRQn interrupt configuration */
  HAL_NVIC_SetPriority(DMA1_Stream2_IRQn, 1, 1);
  HAL_NVIC_EnableIRQ(DMA1_Stream2_IRQn);

}

static void MX_GPIO_Init(void)
{
  GPIO_InitTypeDef GPIO_InitStruct = {0};

  /* GPIO Ports Clock Enable */
  __HAL_RCC_GPIOE_CLK_ENABLE();
  __HAL_RCC_GPIOC_CLK_ENABLE();
  __HAL_RCC_GPIOH_CLK_ENABLE();
  __HAL_RCC_GPIOA_CLK_ENABLE();
  __HAL_RCC_GPIOB_CLK_ENABLE();
  __HAL_RCC_GPIOD_CLK_ENABLE();

  /*Configure GPIO pin Output Level */
  HAL_GPIO_WritePin(ACCEL_NCS3_GPIO_Port, ACCEL_NCS3_Pin, GPIO_PIN_SET);

  /*Configure GPIO pin Output Level */
  HAL_GPIO_WritePin(GPIO_TIMING2_GPIO_Port, GPIO_TIMING2_Pin, GPIO_PIN_RESET);

  /*Configure GPIO pin Output Level */
  HAL_GPIO_WritePin(GPIO_TIMING1_GPIO_Port, GPIO_TIMING1_Pin, GPIO_PIN_RESET);

  /*Configure GPIO pin Output Level */
  HAL_GPIO_WritePin(GPIOA, MUTE_INDICATOR_Pin|MUTE_SIGNAL_Pin, GPIO_PIN_SET);

  /*Configure GPIO pin Output Level */
  HAL_GPIO_WritePin(ACCEL_NCS1_GPIO_Port, ACCEL_NCS1_Pin, GPIO_PIN_SET);

  /*Configure GPIO pin Output Level */
  HAL_GPIO_WritePin(ACCEL_NCS2_GPIO_Port, ACCEL_NCS2_Pin, GPIO_PIN_SET);

  /*Configure GPIO pin Output Level */
  HAL_GPIO_WritePin(RECORD_INDICATOR_GPIO_Port, RECORD_INDICATOR_Pin, GPIO_PIN_RESET);

  /*Configure GPIO pin : ACCEL_INTA3_Pin */
  GPIO_InitStruct.Pin = ACCEL_INTA3_Pin;
  GPIO_InitStruct.Mode = GPIO_MODE_IT_RISING;
  GPIO_InitStruct.Pull = GPIO_NOPULL;
  HAL_GPIO_Init(ACCEL_INTA3_GPIO_Port, &GPIO_InitStruct);

  /*Configure GPIO pin : ACCEL_NCS3_Pin */
  GPIO_InitStruct.Pin = ACCEL_NCS3_Pin;
  GPIO_InitStruct.Mode = GPIO_MODE_OUTPUT_PP;
  GPIO_InitStruct.Pull = GPIO_NOPULL;
  GPIO_InitStruct.Speed = GPIO_SPEED_FREQ_VERY_HIGH;
  HAL_GPIO_Init(ACCEL_NCS3_GPIO_Port, &GPIO_InitStruct);

  /*Configure GPIO pin : ACCEL_INTB3_Pin */
  GPIO_InitStruct.Pin = ACCEL_INTB3_Pin;
  GPIO_InitStruct.Mode = GPIO_MODE_IT_RISING;
  GPIO_InitStruct.Pull = GPIO_NOPULL;
  HAL_GPIO_Init(ACCEL_INTB3_GPIO_Port, &GPIO_InitStruct);

  /*Configure GPIO pin : GPIO_TIMING2_Pin */
  GPIO_InitStruct.Pin = GPIO_TIMING2_Pin;
  GPIO_InitStruct.Mode = GPIO_MODE_OUTPUT_PP;
  GPIO_InitStruct.Pull = GPIO_NOPULL;
  GPIO_InitStruct.Speed = GPIO_SPEED_FREQ_LOW;
  HAL_GPIO_Init(GPIO_TIMING2_GPIO_Port, &GPIO_InitStruct);

  /*Configure GPIO pins : GPIO_TIMING1_Pin MUTE_INDICATOR_Pin MUTE_SIGNAL_Pin */
  GPIO_InitStruct.Pin = GPIO_TIMING1_Pin|MUTE_INDICATOR_Pin|MUTE_SIGNAL_Pin;
  GPIO_InitStruct.Mode = GPIO_MODE_OUTPUT_PP;
  GPIO_InitStruct.Pull = GPIO_NOPULL;
  GPIO_InitStruct.Speed = GPIO_SPEED_FREQ_LOW;
  HAL_GPIO_Init(GPIOA, &GPIO_InitStruct);

  /*Configure GPIO pins : MUTE_BUTTON_Pin RECORD_BUTTON_Pin */
  GPIO_InitStruct.Pin = MUTE_BUTTON_Pin|RECORD_BUTTON_Pin;
  GPIO_InitStruct.Mode = GPIO_MODE_INPUT;
  GPIO_InitStruct.Pull = GPIO_NOPULL;
  HAL_GPIO_Init(GPIOA, &GPIO_InitStruct);

  /*Configure GPIO pin : ACCEL_NCS1_Pin */
  GPIO_InitStruct.Pin = ACCEL_NCS1_Pin;
  GPIO_InitStruct.Mode = GPIO_MODE_OUTPUT_PP;
  GPIO_InitStruct.Pull = GPIO_NOPULL;
  GPIO_InitStruct.Speed = GPIO_SPEED_FREQ_VERY_HIGH;
  HAL_GPIO_Init(ACCEL_NCS1_GPIO_Port, &GPIO_InitStruct);

  /*Configure GPIO pins : ACCEL_INTA1_Pin ACCEL_INTB1_Pin ACCEL_INTA2_Pin ACCEL_INTB2_Pin */
  GPIO_InitStruct.Pin = ACCEL_INTA1_Pin|ACCEL_INTB1_Pin|ACCEL_INTA2_Pin|ACCEL_INTB2_Pin;
  GPIO_InitStruct.Mode = GPIO_MODE_IT_RISING;
  GPIO_InitStruct.Pull = GPIO_NOPULL;
  HAL_GPIO_Init(GPIOD, &GPIO_InitStruct);

  /*Configure GPIO pin : DAC_EXT_Pin */
  GPIO_InitStruct.Pin = DAC_EXT_Pin;
  GPIO_InitStruct.Mode = GPIO_MODE_INPUT;
  GPIO_InitStruct.Pull = GPIO_NOPULL;
  HAL_GPIO_Init(DAC_EXT_GPIO_Port, &GPIO_InitStruct);

  /*Configure GPIO pin : ACCEL_NCS2_Pin */
  GPIO_InitStruct.Pin = ACCEL_NCS2_Pin;
  GPIO_InitStruct.Mode = GPIO_MODE_OUTPUT_PP;
  GPIO_InitStruct.Pull = GPIO_NOPULL;
  GPIO_InitStruct.Speed = GPIO_SPEED_FREQ_VERY_HIGH;
  HAL_GPIO_Init(ACCEL_NCS2_GPIO_Port, &GPIO_InitStruct);

  /*Configure GPIO pin : RECORD_INDICATOR_Pin */
  GPIO_InitStruct.Pin = RECORD_INDICATOR_Pin;
  GPIO_InitStruct.Mode = GPIO_MODE_OUTPUT_PP;
  GPIO_InitStruct.Pull = GPIO_NOPULL;
  GPIO_InitStruct.Speed = GPIO_SPEED_FREQ_LOW;
  HAL_GPIO_Init(RECORD_INDICATOR_GPIO_Port, &GPIO_InitStruct);

  /* EXTI interrupt init*/
  HAL_NVIC_SetPriority(EXTI1_IRQn, 0, 0);
  HAL_NVIC_EnableIRQ(EXTI1_IRQn);

  HAL_NVIC_SetPriority(EXTI2_IRQn, 0, 0);
  HAL_NVIC_EnableIRQ(EXTI2_IRQn);

  HAL_NVIC_SetPriority(EXTI3_IRQn, 0, 0);
  HAL_NVIC_EnableIRQ(EXTI3_IRQn);

  HAL_NVIC_SetPriority(EXTI9_5_IRQn, 0, 0);
  HAL_NVIC_EnableIRQ(EXTI9_5_IRQn);

  HAL_NVIC_SetPriority(EXTI15_10_IRQn, 0, 0);
  HAL_NVIC_EnableIRQ(EXTI15_10_IRQn);

}

 /* MPU Configuration */

void MPU_Config(void)
{
  MPU_Region_InitTypeDef MPU_InitStruct = {0};

  /* Disables the MPU */
  HAL_MPU_Disable();

  /** Initializes and configures the Region and the memory to be protected
  */
  MPU_InitStruct.Enable = MPU_REGION_ENABLE;
  MPU_InitStruct.Number = MPU_REGION_NUMBER0;
  MPU_InitStruct.BaseAddress = 0x0;
  MPU_InitStruct.Size = MPU_REGION_SIZE_4GB;
  MPU_InitStruct.SubRegionDisable = 0x87;
  MPU_InitStruct.TypeExtField = MPU_TEX_LEVEL0;
  MPU_InitStruct.AccessPermission = MPU_REGION_NO_ACCESS;
  MPU_InitStruct.DisableExec = MPU_INSTRUCTION_ACCESS_DISABLE;
  MPU_InitStruct.IsShareable = MPU_ACCESS_SHAREABLE;
  MPU_InitStruct.IsCacheable = MPU_ACCESS_NOT_CACHEABLE;
  MPU_InitStruct.IsBufferable = MPU_ACCESS_NOT_BUFFERABLE;

  HAL_MPU_ConfigRegion(&MPU_InitStruct);
  /* Enables the MPU */
  HAL_MPU_Enable(MPU_PRIVILEGED_DEFAULT);

}

void Error_Handler(void)
{
  __disable_irq();
  while (1)
  {
  }
}
